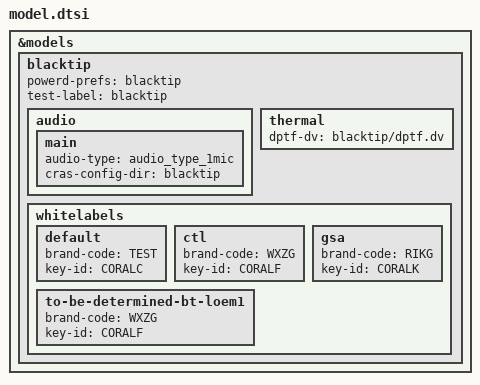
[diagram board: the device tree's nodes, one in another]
/*
 * Copyright 2017 The Chromium OS Authors. All rights reserved.
 *
 * Use of this source code is governed by a BSD-style license that can be
 * found in the LICENSE file.
 */

&models {
	blacktip: blacktip {
		powerd-prefs = "blacktip";
		test-label = "blacktip";
		audio {
			main {
				audio-type = <&audio_type_1mic>;
				cras-config-dir = "blacktip";
			};
		};
		thermal {
			/* Could also point to astronaut/dptf.dv */
			dptf-dv = "blacktip/dptf.dv";
		};
		whitelabels {
			// *default* LOEM
			default {
				brand-code = "TEST";
				key-id = "CORALC";
			};
			ctl {
				brand-code = "WXZG";
				key-id = "CORALF";
			};
			// Workaround to make it compatible with "ctl"
			to-be-determined-bt-loem1 {
				brand-code = "WXZG";
				key-id = "CORALF";
			};
			gsa {
				brand-code = "RIKG";
				key-id = "CORALK";
			};
			// Following are the brand codes allocated but not yet in used.
			//	brand-code = "EDHM";
			//	brand-code = "PWFL";
			//	brand-code = "XBWL";
			//	brand-code = "WNNA";
			//	brand-code = "PCBV";
			//	brand-code = "VXVH";
			//	brand-code = "QPMP";
			//	brand-code = "BMTG";
		};
	};
};
